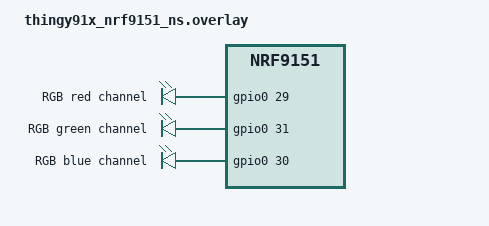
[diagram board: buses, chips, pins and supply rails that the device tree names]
/*
 * Copyright (c) 2025 Nordic Semiconductor ASA
 *
 * SPDX-License-Identifier: LicenseRef-Nordic-5-Clause
 */

/ {
	aliases {
		/delete-property/ led0;
		/delete-property/ led1;
		/delete-property/ led2;
	};

	/delete-node/ leds;

	leds0 {
		compatible = "gpio-leds";
		status = "okay";
		label = "LED0";

		led0: led_0 {
			status = "okay";
			gpios = <&gpio0 29 0>;
			label = "RGB red channel";
		};
	};

	leds1 {
		compatible = "gpio-leds";
		status = "okay";
		label = "LED1";

		led1: led_1 {
			gpios = <&gpio0 31 0>;
			label = "RGB green channel";
		};
	};

	leds2 {
		compatible = "gpio-leds";
		status = "okay";
		label = "LED2";

		led2: led_2 {
			gpios = <&gpio0 30 0>;
			label = "RGB blue channel";
		};
	};
};
